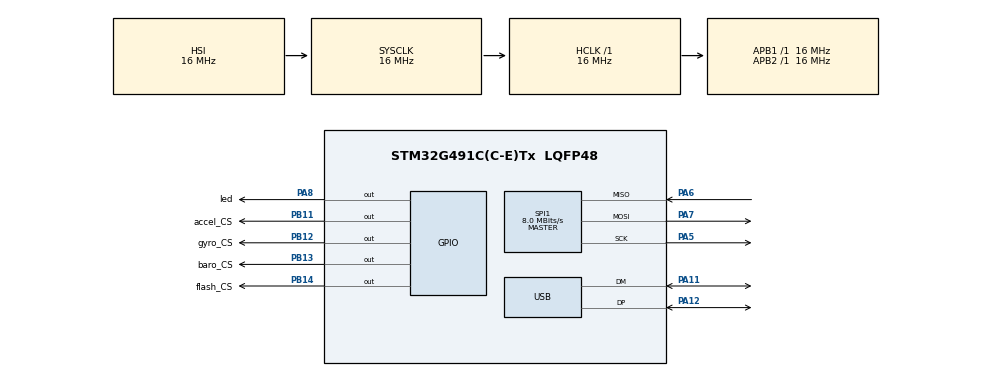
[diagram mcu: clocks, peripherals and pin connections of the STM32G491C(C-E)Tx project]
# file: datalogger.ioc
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Mcu.Family=STM32G4
Mcu.Name=STM32G491C(C-E)Tx
Mcu.Package=LQFP48
NVIC.PriorityGroup=NVIC_PRIORITYGROUP_4
NVIC.TIM6_DAC_IRQn=true\:15\:0\:false\:false\:true\:false\:false\:true\:true
NVIC.TimeBase=TIM6_DAC_IRQn
NVIC.TimeBaseIP=TIM6
PA11.Mode=Device
PA11.Signal=USB_DM
PA12.Mode=Device
PA12.Signal=USB_DP
PA13.Mode=Serial_Wire
PA13.Signal=SYS_JTMS-SWDIO
PA14.Mode=Serial_Wire
PA14.Signal=SYS_JTCK-SWCLK
PA5.Mode=Full_Duplex_Master
PA5.Signal=SPI1_SCK
PA6.Mode=Full_Duplex_Master
PA6.Signal=SPI1_MISO
PA7.Mode=Full_Duplex_Master
PA7.Signal=SPI1_MOSI
PA8.GPIO_Label=led
PA8.Signal=GPIO_Output
PB11.GPIO_Label=accel_CS
PB11.PinState=GPIO_PIN_SET
PB11.Signal=GPIO_Output
PB12.GPIO_Label=gyro_CS
PB12.PinState=GPIO_PIN_SET
PB12.Signal=GPIO_Output
PB13.GPIO_Label=baro_CS
PB13.PinState=GPIO_PIN_SET
PB13.Signal=GPIO_Output
PB14.GPIO_Label=flash_CS
PB14.PinState=GPIO_PIN_SET
PB14.Signal=GPIO_Output
PC14-OSC32_IN.Mode=LSE-External-Oscillator
PC14-OSC32_IN.Signal=RCC_OSC32_IN
PC15-OSC32_OUT.Mode=LSE-External-Oscillator
PC15-OSC32_OUT.Signal=RCC_OSC32_OUT
PF0-OSC_IN.Mode=HSE-External-Oscillator
PF0-OSC_IN.Signal=RCC_OSC_IN
PF1-OSC_OUT.Mode=HSE-External-Oscillator
PF1-OSC_OUT.Signal=RCC_OSC_OUT
ProjectManager.HeapSize=0x200
ProjectManager.StackSize=0x400
ProjectManager.TargetToolchain=CMake
RCC.AHBFreq_Value=16000000
RCC.APB1Freq_Value=16000000
RCC.APB1TimFreq_Value=16000000
RCC.APB2Freq_Value=16000000
RCC.APB2TimFreq_Value=16000000
RCC.CortexFreq_Value=16000000
RCC.EXTERNAL_CLOCK_VALUE=12288000
RCC.HCLKFreq_Value=16000000
RCC.HSE_VALUE=8000000
RCC.HSI48_VALUE=48000000
RCC.HSI_VALUE=16000000
RCC.SYSCLKFreq_VALUE=16000000
RCC.VCOOutputFreq_Value=128000000
SPI1.BaudRatePrescaler=SPI_BAUDRATEPRESCALER_2
SPI1.CLKPhase=SPI_PHASE_1EDGE
SPI1.CLKPolarity=SPI_POLARITY_LOW
SPI1.CalculateBaudRate=8.0 MBits/s
SPI1.DataSize=SPI_DATASIZE_8BIT
SPI1.Direction=SPI_DIRECTION_2LINES
SPI1.FirstBit=SPI_FIRSTBIT_MSB
SPI1.Mode=SPI_MODE_MASTER
SPI1.NSS=SPI_NSS_SOFT
SPI1.VirtualType=VM_MASTER
STMicroelectronics.X-CUBE-AZRTOS-G4.2.0.0.REG_UX_DEVICE_DFU=0
STMicroelectronics.X-CUBE-AZRTOS-G4.2.0.0.ThreadXCcRTOSJjThreadXJjCore=true
STMicroelectronics.X-CUBE-AZRTOS-G4.2.0.0.ThreadXCcRTOSJjThreadXJjLowOoPowerOosupport=true
STMicroelectronics.X-CUBE-AZRTOS-G4.2.0.0.ThreadXCcRTOSJjThreadXJjPerformanceInfo=true
STMicroelectronics.X-CUBE-AZRTOS-G4.2.0.0.ThreadXCcRTOSJjThreadXJjTraceXOosupport=true
STMicroelectronics.X-CUBE-AZRTOS-G4.2.0.0.USBXCcUSBJjUSBXJjCoreSystem=true
STMicroelectronics.X-CUBE-AZRTOS-G4.2.0.0.USBXCcUSBJjUSBXJjUXOoDeviceOoClassOoCDCOoACM=true
STMicroelectronics.X-CUBE-AZRTOS-G4.2.0.0.USBXCcUSBJjUSBXJjUXOoDeviceOoCoreStack=true
STMicroelectronics.X-CUBE-AZRTOS-G4.2.0.0.USBD_CDCACM_EPINCMD_ADDR=2
STMicroelectronics.X-CUBE-AZRTOS-G4.2.0.0.USBD_PRODUCT_STRING=UBSEDS CrashNBurn Datalogger
STMicroelectronics.X-CUBE-AZRTOS-G4.2.0.0.USBX_DEVICE_APP_THREAD_Size=2048
STMicroelectronics.X-CUBE-AZRTOS-G4.2.0.0.USBX_DEVICE_SYS_SIZE=20480
STMicroelectronics.X-CUBE-AZRTOS-G4.2.0.0.UX_DEVICE_APP_MEM_POOL_SIZE=24576
STMicroelectronics.X-CUBE-AZRTOS-G4.2.0.0_IsAnAzureRtosMw=true
VP_STMicroelectronics.X-CUBE-AZRTOS-G4_VS_RTOSJjThreadX_6.2.0_2.0.0.Mode=RTOSJjThreadX
VP_STMicroelectronics.X-CUBE-AZRTOS-G4_VS_USBJjUSBX_6.2.0_2.0.0.Mode=USBJjUSBX
VP_SYS_VS_DBSignals.Mode=DisableDeadBatterySignals
VP_SYS_VS_tim6.Mode=TIM6
board=custom

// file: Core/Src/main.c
/* USER CODE BEGIN Header */
/**
  ******************************************************************************
  * @file           : main.c
  * @brief          : Main program body
  ******************************************************************************
  * @attention
  *
  * Copyright (c) 2026 STMicroelectronics.
  * All rights reserved.
  *
  * This software is licensed under terms that can be found in the LICENSE file
  * in the root directory of this software component.
  * If no LICENSE file comes with this software, it is provided AS-IS.
  *
  ******************************************************************************
  */
/* USER CODE END Header */
#include "app_threadx.h"
#include "tx_api.h"
#include "w25q32jv.h"
#include "main.h"

SPI_HandleTypeDef hspi1;

PCD_HandleTypeDef hpcd_USB_FS;

void SystemClock_Config(void);
static void MX_GPIO_Init(void);
static void MX_SPI1_Init(void);
static void MX_USB_PCD_Init(void);

int main(void)
{

  /* MCU Configuration--------------------------------------------------------*/

  /* Reset of all peripherals, Initializes the Flash interface and the Systick. */
  HAL_Init();

  /* Configure the system clock */
  SystemClock_Config();

  /* USER CODE BEGIN SysInit */
  /* Trim the USB HSI48 clock against the host's 1 kHz SOF packets. */
  RCC_CRSInitTypeDef crs = {0};
  __HAL_RCC_CRS_CLK_ENABLE();
  crs.Prescaler = RCC_CRS_SYNC_DIV1;
  crs.Source = RCC_CRS_SYNC_SOURCE_USB;
  crs.Polarity = RCC_CRS_SYNC_POLARITY_RISING;
  crs.ReloadValue = __HAL_RCC_CRS_RELOADVALUE_CALCULATE(48000000, 1000);
  crs.ErrorLimitValue = RCC_CRS_ERRORLIMIT_DEFAULT;
  crs.HSI48CalibrationValue = RCC_CRS_HSI48CALIBRATION_DEFAULT;
  HAL_RCCEx_CRSConfig(&crs);
  /* USER CODE END SysInit */

  /* Initialize all configured peripherals */
  MX_GPIO_Init();
  MX_SPI1_Init();
  MX_USB_PCD_Init();

  MX_ThreadX_Init();

  /* We should never get here as control is now taken by the scheduler */

  /* Infinite loop */
  while (1)
  {

  }
}

void SystemClock_Config(void)
{
  RCC_OscInitTypeDef RCC_OscInitStruct = {0};
  RCC_ClkInitTypeDef RCC_ClkInitStruct = {0};

  /** Configure the main internal regulator output voltage
  */
  HAL_PWREx_ControlVoltageScaling(PWR_REGULATOR_VOLTAGE_SCALE1);

  /** Initializes the RCC Oscillators according to the specified parameters
  * in the RCC_OscInitTypeDef structure.
  */
  RCC_OscInitStruct.OscillatorType = RCC_OSCILLATORTYPE_HSI|RCC_OSCILLATORTYPE_HSI48;
  RCC_OscInitStruct.HSIState = RCC_HSI_ON;
  RCC_OscInitStruct.HSICalibrationValue = RCC_HSICALIBRATION_DEFAULT;
  RCC_OscInitStruct.HSI48State = RCC_HSI48_ON;
  RCC_OscInitStruct.PLL.PLLState = RCC_PLL_NONE;
  if (HAL_RCC_OscConfig(&RCC_OscInitStruct) != HAL_OK)
  {
    Error_Handler();
  }

  /** Initializes the CPU, AHB and APB buses clocks
  */
  RCC_ClkInitStruct.ClockType = RCC_CLOCKTYPE_HCLK|RCC_CLOCKTYPE_SYSCLK
                              |RCC_CLOCKTYPE_PCLK1|RCC_CLOCKTYPE_PCLK2;
  RCC_ClkInitStruct.SYSCLKSource = RCC_SYSCLKSOURCE_HSI;
  RCC_ClkInitStruct.AHBCLKDivider = RCC_SYSCLK_DIV1;
  RCC_ClkInitStruct.APB1CLKDivider = RCC_HCLK_DIV1;
  RCC_ClkInitStruct.APB2CLKDivider = RCC_HCLK_DIV1;

  if (HAL_RCC_ClockConfig(&RCC_ClkInitStruct, FLASH_LATENCY_0) != HAL_OK)
  {
    Error_Handler();
  }
}

static void MX_SPI1_Init(void)
{

  /* SPI1 parameter configuration*/
  hspi1.Instance = SPI1;
  hspi1.Init.Mode = SPI_MODE_MASTER;
  hspi1.Init.Direction = SPI_DIRECTION_2LINES;
  hspi1.Init.DataSize = SPI_DATASIZE_8BIT;
  hspi1.Init.CLKPolarity = SPI_POLARITY_LOW;
  hspi1.Init.CLKPhase = SPI_PHASE_1EDGE;
  hspi1.Init.NSS = SPI_NSS_SOFT;
  hspi1.Init.BaudRatePrescaler = SPI_BAUDRATEPRESCALER_2;
  hspi1.Init.FirstBit = SPI_FIRSTBIT_MSB;
  hspi1.Init.TIMode = SPI_TIMODE_DISABLE;
  hspi1.Init.CRCCalculation = SPI_CRCCALCULATION_DISABLE;
  hspi1.Init.CRCPolynomial = 7;
  hspi1.Init.CRCLength = SPI_CRC_LENGTH_DATASIZE;
  hspi1.Init.NSSPMode = SPI_NSS_PULSE_ENABLE;
  if (HAL_SPI_Init(&hspi1) != HAL_OK)
  {
    Error_Handler();
  }

}

static void MX_USB_PCD_Init(void)
{

  hpcd_USB_FS.Instance = USB;
  hpcd_USB_FS.Init.dev_endpoints = 8;
  hpcd_USB_FS.Init.speed = PCD_SPEED_FULL;
  hpcd_USB_FS.Init.phy_itface = PCD_PHY_EMBEDDED;
  hpcd_USB_FS.Init.Sof_enable = DISABLE;
  hpcd_USB_FS.Init.low_power_enable = DISABLE;
  hpcd_USB_FS.Init.lpm_enable = DISABLE;
  hpcd_USB_FS.Init.battery_charging_enable = DISABLE;
  if (HAL_PCD_Init(&hpcd_USB_FS) != HAL_OK)
  {
    Error_Handler();
  }

}

static void MX_GPIO_Init(void)
{
  GPIO_InitTypeDef GPIO_InitStruct = {0};

  /* GPIO Ports Clock Enable */
  __HAL_RCC_GPIOC_CLK_ENABLE();
  __HAL_RCC_GPIOF_CLK_ENABLE();
  __HAL_RCC_GPIOA_CLK_ENABLE();
  __HAL_RCC_GPIOB_CLK_ENABLE();

  /*Configure GPIO pin Output Level */
  HAL_GPIO_WritePin(GPIOB, accel_CS_Pin|gyro_CS_Pin|baro_CS_Pin|flash_CS_Pin, GPIO_PIN_SET);

  /*Configure GPIO pin Output Level */
  HAL_GPIO_WritePin(led_GPIO_Port, led_Pin, GPIO_PIN_RESET);

  /*Configure GPIO pins : accel_CS_Pin gyro_CS_Pin baro_CS_Pin flash_CS_Pin */
  GPIO_InitStruct.Pin = accel_CS_Pin|gyro_CS_Pin|baro_CS_Pin|flash_CS_Pin;
  GPIO_InitStruct.Mode = GPIO_MODE_OUTPUT_PP;
  GPIO_InitStruct.Pull = GPIO_NOPULL;
  GPIO_InitStruct.Speed = GPIO_SPEED_FREQ_LOW;
  HAL_GPIO_Init(GPIOB, &GPIO_InitStruct);

  /*Configure GPIO pin : led_Pin */
  GPIO_InitStruct.Pin = led_Pin;
  GPIO_InitStruct.Mode = GPIO_MODE_OUTPUT_PP;
  GPIO_InitStruct.Pull = GPIO_NOPULL;
  GPIO_InitStruct.Speed = GPIO_SPEED_FREQ_LOW;
  HAL_GPIO_Init(led_GPIO_Port, &GPIO_InitStruct);

}

void HAL_TIM_PeriodElapsedCallback(TIM_HandleTypeDef *htim)
{
  if (htim->Instance == TIM6)
  {
    HAL_IncTick();
  }
}

void Error_Handler(void)
{
  __disable_irq();
  while (1)
  {
  }
}
